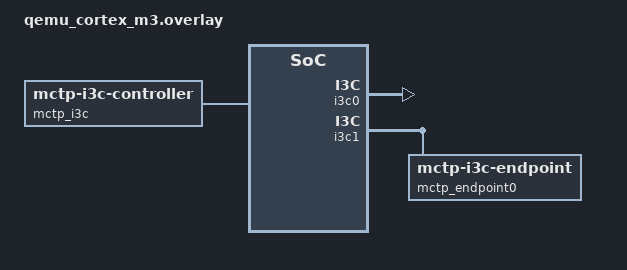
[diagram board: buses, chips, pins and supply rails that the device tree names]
/ {
	test_fixed_clk: test-fixed-clock {
		compatible = "fixed-clock";
		clock-frequency = <200000000>;
		#clock-cells = <0>;
	};

	i3c0: i3c@88888888 {
		compatible = "cdns,i3c";
		#address-cells = <3>;
		#size-cells = <0>;
		reg = <0x88888888 0x400>;
		interrupt-parent = <&nvic>;
		interrupts = <4 1>;
		input-clock-frequency = <200000000>;
		i3c-scl-hz = <12500000>;
		i2c-scl-hz = <400000>;
	};

	i3c1: i3c@cccccccc {
		compatible = "snps,designware-i3c";
		#address-cells = <3>;
		#size-cells = <0>;
		reg = <0xcccccccc 0x400>;
		interrupt-parent = <&nvic>;
		interrupts = <8 1>;
		clocks = <&test_fixed_clk>;
		i3c-scl-hz = <12500000>;
		i2c-scl-hz = <400000>;

		mctp_endpoint0: mctp_endpoint0@00ABCD00000011 {
			compatible = "zephyr,mctp-i3c-endpoint";
			reg = <0x00 0xABCD 0x00000011>;
			status = "okay";
		};
	};

	mctp_i3c: mctp_i3c {
		compatible = "zephyr,mctp-i3c-controller";
		endpoints = <&mctp_endpoint0>;
	};
};
